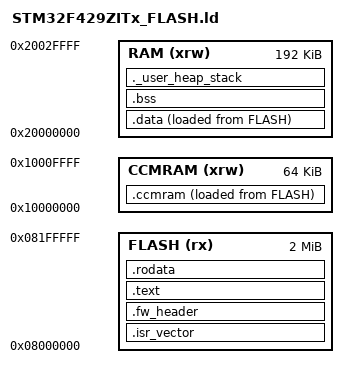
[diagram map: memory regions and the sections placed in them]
/* Entry Point */
ENTRY(Reset_Handler)

/* Highest address of the user mode stack */
_estack = ORIGIN(RAM) + LENGTH(RAM);    /* end of RAM */

/* Generate a link error if heap and stack don't fit into RAM */
_Min_Heap_Size = 0x200;       /* required amount of heap  */
_Min_Stack_Size = 0x400;      /* required amount of stack */
__fw_header_offset = 0x200;   /* firmware header offset */
__fw_header_size  = 32;       /* firmware header size */

/* Specify the memory areas */
MEMORY
{
  RAM (xrw)     : ORIGIN = 0x20000000,  LENGTH = 192K
  CCMRAM (xrw)  : ORIGIN = 0x10000000,  LENGTH = 64K
  FLASH (rx)    : ORIGIN = 0x8000000,   LENGTH = 2048K
}

/* Define output sections */
SECTIONS
{
  /* The startup code goes first into FLASH */
  .isr_vector :
  {
    . = ALIGN(4);
    KEEP(*(.isr_vector)) /* Startup code */
    . = ALIGN(4);
  } >FLASH

  .fw_header : ALIGN(4)
  {
    FILL(0xFF)
    . = ORIGIN(FLASH) + __fw_header_offset;
    KEEP(*(.fw_header))
    . = . + __fw_header_size;
  } >FLASH

  /* The program code and other data goes into FLASH */
  .text :
  {
    . = ALIGN(4);
    *(.text)           /* .text sections (code) */
    *(.text*)          /* .text* sections (code) */
    *(.glue_7)         /* glue arm to thumb code */
    *(.glue_7t)        /* glue thumb to arm code */

    . = ALIGN(4);
    _etext = .;        /* define a global symbols at end of code */
  } >FLASH

  /* Constant data goes into FLASH */
  .rodata :
  {
    . = ALIGN(4);
    *(.rodata)         /* .rodata sections (constants, strings, etc.) */
    *(.rodata*)        /* .rodata* sections (constants, strings, etc.) */
    . = ALIGN(4);
  } >FLASH

  /* used by the startup to initialize data */
  _sidata = LOADADDR(.data);

  /* Initialized data sections goes into RAM, load LMA copy after code */
  .data : 
  {
    . = ALIGN(4);
    _sdata = .;        /* create a global symbol at data start */
    *(.data)           /* .data sections */
    *(.data*)          /* .data* sections */

    . = ALIGN(4);
    _edata = .;        /* define a global symbol at data end */
  } >RAM AT> FLASH

  _siccmram = LOADADDR(.ccmram);

  /* CCM-RAM section 
  * 
  * IMPORTANT NOTE! 
  * If initialized variables will be placed in this section,
  * the startup code needs to be modified to copy the init-values.  
  */
  .ccmram :
  {
    . = ALIGN(4);
    _sccmram = .;       /* create a global symbol at ccmram start */
    *(.ccmram)
    *(.ccmram*)
    
    . = ALIGN(4);
    _eccmram = .;       /* create a global symbol at ccmram end */
  } >CCMRAM AT> FLASH

  
  /* Uninitialized data section */
  . = ALIGN(4);
  .bss :
  {
    /* This is used by the startup in order to initialize the .bss secion */
    _sbss = .;         /* define a global symbol at bss start */
    __bss_start__ = _sbss;
    *(.bss)
    *(.bss*)
    *(COMMON)

    . = ALIGN(4);
    _ebss = .;         /* define a global symbol at bss end */
    __bss_end__ = _ebss;
  } >RAM

  /* User_heap_stack section, used to check that there is enough RAM left */
  ._user_heap_stack :
  {
    . = ALIGN(8);
    PROVIDE ( end = . );
    PROVIDE ( _end = . );
    . = . + _Min_Heap_Size;
    . = . + _Min_Stack_Size;
    . = ALIGN(8);
  } >RAM  

  /* Remove information from the standard libraries */
  /DISCARD/ :
  {
    libc.a ( * )
    libm.a ( * )
    libgcc.a ( * )
  }

  .ARM.attributes 0 : { *(.ARM.attributes) }
}
